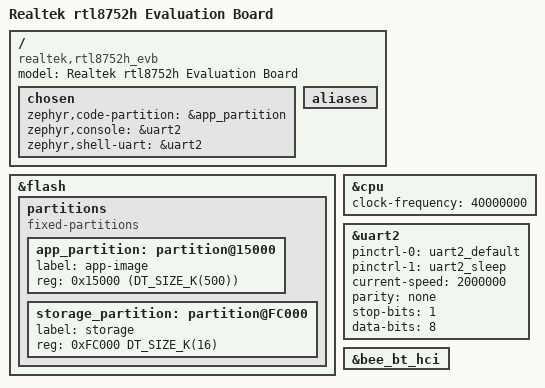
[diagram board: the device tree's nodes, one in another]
/*
 * Copyright (c) 2024 Realtek Semiconductor Corp.
 *
 * SPDX-License-Identifier: Apache-2.0
 */

/dts-v1/;
#include <realtek/bee/rtl8752hkf.dtsi>
#include "rtl8752h_evb-pinctrl.dtsi"

/ {
	model = "Realtek rtl8752h Evaluation Board";
	compatible = "realtek,rtl8752h_evb";

	chosen {
		zephyr,code-partition = &app_partition;
		zephyr,console = &uart2;
		zephyr,shell-uart = &uart2;
	};

	/* These aliases are provided for compatibility with samples */
	aliases {
	};

};

&flash {
	partitions {
		compatible = "fixed-partitions";
		#address-cells = <1>;
		#size-cells = <1>;
		app_partition: partition@15000 {
			label = "app-image";
			reg = <0x15000 (DT_SIZE_K(500))>;
		};
		storage_partition: partition@FC000 {
			label = "storage";
			reg = <0xFC000 DT_SIZE_K(16)>;
		};
	};
};

&cpu {
	clock-frequency = <40000000>;
};

&uart2 {
	pinctrl-0 = <&uart2_default>;
	pinctrl-1 = <&uart2_sleep>;
	pinctrl-names = "default", "sleep";
	status = "okay";
	current-speed = <2000000>;
	parity = "none";
	stop-bits = "1";
	data-bits = <8>;
};

&bee_bt_hci {
	status= "okay";
};
